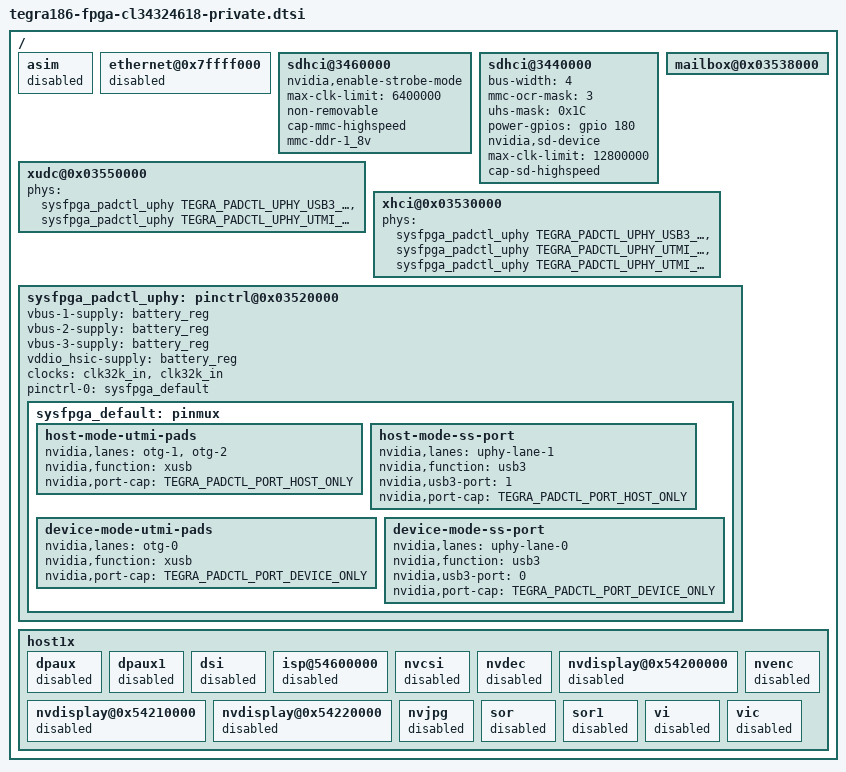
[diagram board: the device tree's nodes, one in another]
/*
 * arch/arm64/boot/dts/tegra186-fpga-cl34324618-private.dtsi
 *
 * Copyright (c) 2015, NVIDIA CORPORATION.  All rights reserved.
 *
 * This program is free software; you can redistribute it and/or modify
 * it under the terms of the GNU General Public License as published by
 * the Free Software Foundation; version 2 of the License.
 *
 * This program is distributed in the hope that it will be useful, but WITHOUT
 * ANY WARRANTY; without even the implied warranty of MERCHANTABILITY or
 * FITNESS FOR A PARTICULAR PURPOSE.  See the GNU General Public License for
 * more details.
 *
 * You should have received a copy of the GNU General Public License along
 * with this program; if not, write to the Free Software Foundation, Inc.,
 * 51 Franklin Street, Fifth Floor, Boston, MA  02110-1301, USA.
 *
 */
#include "../../../../../include/dt-bindings/pinctrl/pinctrl-tegra-padctl-uphy.h"

/ {
	asim {
		status = "disabled";
	};

	ethernet@0x7ffff000 {
		status = "disabled";
	};

	sdhci@3460000 {
		nvidia,enable-strobe-mode;
		max-clk-limit = <6400000>;
		non-removable;
		cap-mmc-highspeed;
		mmc-ddr-1_8v;
		status = "okay";
        };

	sdhci@3440000 {
		bus-width = <4>;
		mmc-ocr-mask = <3>;
		uhs-mask = <0x1C>;
		power-gpios = <&gpio 180 0>;
		nvidia,sd-device;
		max-clk-limit = <12800000>;
		power-gpios = <&gpio 180 0>;
		cap-sd-highspeed;
		status = "okay";
        };
	mailbox@0x03538000 {
		status = "okay";
	};

	xudc@0x03550000 {
		status = "okay";

		phys = <&sysfpga_padctl_uphy TEGRA_PADCTL_UPHY_USB3_P(0)>,
			<&sysfpga_padctl_uphy TEGRA_PADCTL_UPHY_UTMI_P(0)>;
		phy-names = "usb3", "usb2";
	};

	xhci@0x03530000 {
		status = "okay";

		phys = 	<&sysfpga_padctl_uphy TEGRA_PADCTL_UPHY_USB3_P(1)>,
			<&sysfpga_padctl_uphy TEGRA_PADCTL_UPHY_UTMI_P(1)>,
			<&sysfpga_padctl_uphy TEGRA_PADCTL_UPHY_UTMI_P(2)>;

		phy-names = "usb3-1", "utmi-1", "utmi-2";
	};

	sysfpga_padctl_uphy: pinctrl@0x03520000 {
		status = "okay";

		vbus-1-supply = <&battery_reg>;
		vbus-2-supply = <&battery_reg>;
		vbus-3-supply = <&battery_reg>;
		vddio_hsic-supply = <&battery_reg>;

		/* use virtual clocks for fpga */
		clocks = <&clk32k_in>, <&clk32k_in>;
		pinctrl-0 = <&sysfpga_default>;
		pinctrl-names = "default";
		sysfpga_default: pinmux {
			host-mode-utmi-pads {
				nvidia,lanes = "otg-1", "otg-2";
				nvidia,function = "xusb";
				nvidia,port-cap = <TEGRA_PADCTL_PORT_HOST_ONLY>;
			};
			host-mode-ss-port {
				nvidia,lanes = "uphy-lane-1";
				nvidia,function = "usb3";
				nvidia,usb3-port = <1>;
				nvidia,port-cap = <TEGRA_PADCTL_PORT_HOST_ONLY>;
			};
			device-mode-utmi-pads {
				nvidia,lanes = "otg-0";
				nvidia,function = "xusb";
				nvidia,port-cap = <TEGRA_PADCTL_PORT_DEVICE_ONLY>;
			};
			device-mode-ss-port {
				nvidia,lanes = "uphy-lane-0";
				nvidia,function = "usb3";
				nvidia,usb3-port = <0>;
				nvidia,port-cap = <TEGRA_PADCTL_PORT_DEVICE_ONLY>;
			};
		};
	};

	host1x: host1x {
		dpaux {
			status = "disabled";
		};

		dpaux1 {
			status = "disabled";
		};

		dsi {
			status = "disabled";
		};

		isp@54600000 {
			status = "disabled";
		};

		nvcsi {
			status = "disabled";
		};

		nvdec {
			status = "disabled";
		};

		nvdisplay@0x54200000 {
			status = "disabled";
		};

		nvdisplay@0x54210000 {
			status = "disabled";
		};

		nvdisplay@0x54220000 {
			status = "disabled";
		};

		nvenc {
			status = "disabled";
		};

		nvjpg {
			status = "disabled";
		};

		sor {
			status = "disabled";
		};

		sor1 {
			status = "disabled";
		};

		vi {
			status = "disabled";
		};

		vic {
			status = "disabled";
		};
	};
};
